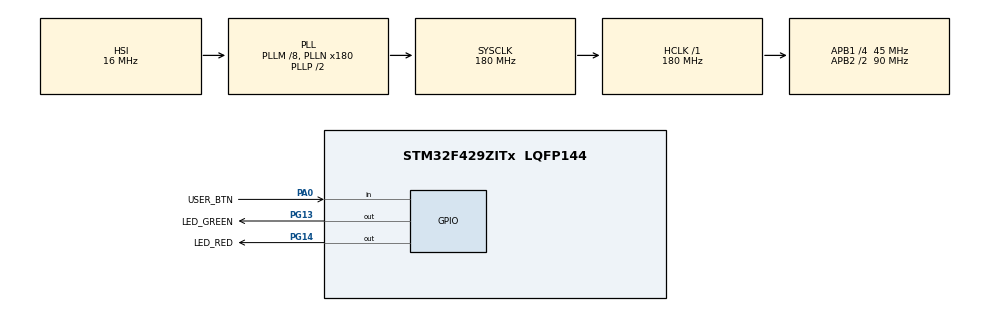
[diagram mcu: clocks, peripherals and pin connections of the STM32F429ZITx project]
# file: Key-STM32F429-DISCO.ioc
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Mcu.Family=STM32F4
Mcu.Name=STM32F429ZITx
Mcu.Package=LQFP144
NVIC.PriorityGroup=NVIC_PRIORITYGROUP_4
NVIC.TIM7_IRQn=true\:0\:0\:false\:false\:true\:true\:true
PA0/WKUP.GPIO_Label=USER_BTN
PA0/WKUP.Signal=GPIO_Input
PG13.GPIO_Label=LED_GREEN
PG13.Signal=GPIO_Output
PG14.GPIO_Label=LED_RED
PG14.Signal=GPIO_Output
ProjectManager.HeapSize=0x200
ProjectManager.StackSize=0x400
ProjectManager.TargetToolchain=MDK-ARM V5.27
RCC.48MHZClocksFreq_Value=120000000
RCC.AHBFreq_Value=180000000
RCC.APB1CLKDivider=RCC_HCLK_DIV4
RCC.APB1Freq_Value=45000000
RCC.APB1TimFreq_Value=90000000
RCC.APB2CLKDivider=RCC_HCLK_DIV2
RCC.APB2Freq_Value=90000000
RCC.APB2TimFreq_Value=180000000
RCC.CortexFreq_Value=180000000
RCC.HCLKFreq_Value=180000000
RCC.HSE_VALUE=8000000
RCC.HSI_VALUE=16000000
RCC.LSE_VALUE=32768
RCC.PLLM=8
RCC.PLLN=180
RCC.PLLQ=3
RCC.PLLSAIN=50
RCC.SYSCLKFreq_VALUE=180000000
RCC.SYSCLKSource=RCC_SYSCLKSOURCE_PLLCLK
RCC.VCOOutputFreq_Value=360000000
TIM7.Period=49999
TIM7.Prescaler=999
VP_TIM7_VS_ClockSourceINT.Mode=Enable_Timer
board=STM32F429I-DISC1

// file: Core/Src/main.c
/* USER CODE BEGIN Header */
/**
  ******************************************************************************
  * @file           : main.c
  * @brief          : Main program body
  ******************************************************************************
  * @attention
  *
  * <h2><center>&copy; Copyright (c) 2022 STMicroelectronics.
  * All rights reserved.</center></h2>
  *
  * This software component is licensed by ST under BSD 3-Clause license,
  * the "License"; You may not use this file except in compliance with the
  * License. You may obtain a copy of the License at:
  *                        opensource.org/licenses/BSD-3-Clause
  *
  ******************************************************************************
  */
/* USER CODE END Header */
#include "main.h"

/* USER CODE BEGIN Includes */
#include "Key.h"
#include "KeyPort.h"

#if !KEY_MULTI_CALLBACK
  #error "You ust enable KEY_MULTI_CALLBACK"
#endif

/* USER CODE END Includes */

TIM_HandleTypeDef htim7;

/* USER CODE BEGIN PV */
static const Key_PinConfig USER_BTN_CONFIG = {
  USER_BTN_GPIO_Port,
  USER_BTN_Pin,
};

#if KEY_MAX_NUM == -1
  static Key userBtn;
#else
  static Key* userBtn;
#endif
/* USER CODE END PV */

void SystemClock_Config(void);
static void MX_GPIO_Init(void);
static void MX_TIM7_Init(void);
/* USER CODE BEGIN PFP */
Key_HandleStatus Btn_onPress(Key* key, Key_State state);
Key_HandleStatus Btn_onRelease(Key* key, Key_State state);
Key_HandleStatus Btn_onHold(Key* key, Key_State state);
/* USER CODE END PFP */

/* USER CODE BEGIN 0 */
void Key_initPin(const Key_PinConfig* config);
uint8_t Key_readPin(const Key_PinConfig* config);

#if KEY_USE_DEINIT
void Key_deInitPin(const Key_PinConfig* config);
#endif

static const Key_Driver KEY_DRIVER = {
  Key_readPin,
  Key_initPin,
#if KEY_USE_DEINIT
  Key_deInitPin,
#endif
};
/* USER CODE END 0 */

int main(void)
{

  /* MCU Configuration--------------------------------------------------------*/

  /* Reset of all peripherals, Initializes the Flash interface and the Systick. */
  HAL_Init();

  /* Configure the system clock */
  SystemClock_Config();

  /* Initialize all configured peripherals */
  MX_GPIO_Init();
  MX_TIM7_Init();
  /* USER CODE BEGIN 2 */
  Key_init(&KEY_DRIVER);

#if KEY_MAX_NUM == -1
  Key_add(&userBtn, &USER_BTN_CONFIG);
  Key_onPressed(&userBtn, Btn_onPress);
  Key_onReleased(&userBtn, Btn_onRelease);
  Key_onHold(&userBtn, Btn_onHold);
#else
  userBtn = Key_new();
  Key_add(userBtn, &USER_BTN_CONFIG);
  Key_onPressed(userBtn, Btn_onPress);
  Key_onReleased(userBtn, Btn_onRelease);
  Key_onHold(userBtn, Btn_onHold);
#endif
  /* USER CODE END 2 */

  /* Infinite loop */
  while (1)
  {

  }
}

void SystemClock_Config(void)
{
  RCC_OscInitTypeDef RCC_OscInitStruct = {0};
  RCC_ClkInitTypeDef RCC_ClkInitStruct = {0};

  /** Configure the main internal regulator output voltage
  */
  __HAL_RCC_PWR_CLK_ENABLE();
  __HAL_PWR_VOLTAGESCALING_CONFIG(PWR_REGULATOR_VOLTAGE_SCALE1);
  /** Initializes the RCC Oscillators according to the specified parameters
  * in the RCC_OscInitTypeDef structure.
  */
  RCC_OscInitStruct.OscillatorType = RCC_OSCILLATORTYPE_HSI;
  RCC_OscInitStruct.HSIState = RCC_HSI_ON;
  RCC_OscInitStruct.HSICalibrationValue = RCC_HSICALIBRATION_DEFAULT;
  RCC_OscInitStruct.PLL.PLLState = RCC_PLL_ON;
  RCC_OscInitStruct.PLL.PLLSource = RCC_PLLSOURCE_HSI;
  RCC_OscInitStruct.PLL.PLLM = 8;
  RCC_OscInitStruct.PLL.PLLN = 180;
  RCC_OscInitStruct.PLL.PLLP = RCC_PLLP_DIV2;
  RCC_OscInitStruct.PLL.PLLQ = 3;
  if (HAL_RCC_OscConfig(&RCC_OscInitStruct) != HAL_OK)
  {
    Error_Handler();
  }
  /** Activate the Over-Drive mode
  */
  if (HAL_PWREx_EnableOverDrive() != HAL_OK)
  {
    Error_Handler();
  }
  /** Initializes the CPU, AHB and APB buses clocks
  */
  RCC_ClkInitStruct.ClockType = RCC_CLOCKTYPE_HCLK|RCC_CLOCKTYPE_SYSCLK
                              |RCC_CLOCKTYPE_PCLK1|RCC_CLOCKTYPE_PCLK2;
  RCC_ClkInitStruct.SYSCLKSource = RCC_SYSCLKSOURCE_PLLCLK;
  RCC_ClkInitStruct.AHBCLKDivider = RCC_SYSCLK_DIV1;
  RCC_ClkInitStruct.APB1CLKDivider = RCC_HCLK_DIV4;
  RCC_ClkInitStruct.APB2CLKDivider = RCC_HCLK_DIV2;

  if (HAL_RCC_ClockConfig(&RCC_ClkInitStruct, FLASH_LATENCY_5) != HAL_OK)
  {
    Error_Handler();
  }
}

static void MX_TIM7_Init(void)
{

  /* USER CODE BEGIN TIM7_Init 0 */
  // Perido is 50ms
  /* USER CODE END TIM7_Init 0 */

  TIM_MasterConfigTypeDef sMasterConfig = {0};

  htim7.Instance = TIM7;
  htim7.Init.Prescaler = 999;
  htim7.Init.CounterMode = TIM_COUNTERMODE_UP;
  htim7.Init.Period = 4499;
  htim7.Init.AutoReloadPreload = TIM_AUTORELOAD_PRELOAD_DISABLE;
  if (HAL_TIM_Base_Init(&htim7) != HAL_OK)
  {
    Error_Handler();
  }
  sMasterConfig.MasterOutputTrigger = TIM_TRGO_RESET;
  sMasterConfig.MasterSlaveMode = TIM_MASTERSLAVEMODE_DISABLE;
  if (HAL_TIMEx_MasterConfigSynchronization(&htim7, &sMasterConfig) != HAL_OK)
  {
    Error_Handler();
  }
  /* USER CODE BEGIN TIM7_Init 2 */
  HAL_TIM_Base_Start_IT(&htim7);
  /* USER CODE END TIM7_Init 2 */

}

static void MX_GPIO_Init(void)
{
  GPIO_InitTypeDef GPIO_InitStruct = {0};

  /* GPIO Ports Clock Enable */
  __HAL_RCC_GPIOA_CLK_ENABLE();
  __HAL_RCC_GPIOG_CLK_ENABLE();

  /*Configure GPIO pin Output Level */
  HAL_GPIO_WritePin(GPIOG, LED_GREEN_Pin|LED_RED_Pin, GPIO_PIN_RESET);

  /*Configure GPIO pin : USER_BTN_Pin */
  GPIO_InitStruct.Pin = USER_BTN_Pin;
  GPIO_InitStruct.Mode = GPIO_MODE_INPUT;
  GPIO_InitStruct.Pull = GPIO_NOPULL;
  HAL_GPIO_Init(USER_BTN_GPIO_Port, &GPIO_InitStruct);

  /*Configure GPIO pins : LED_GREEN_Pin LED_RED_Pin */
  GPIO_InitStruct.Pin = LED_GREEN_Pin|LED_RED_Pin;
  GPIO_InitStruct.Mode = GPIO_MODE_OUTPUT_PP;
  GPIO_InitStruct.Pull = GPIO_NOPULL;
  GPIO_InitStruct.Speed = GPIO_SPEED_FREQ_LOW;
  HAL_GPIO_Init(GPIOG, &GPIO_InitStruct);

}

/* USER CODE BEGIN 4 */
Key_HandleStatus Btn_onPress(Key* key, Key_State state) {
  HAL_GPIO_WritePin(LED_RED_GPIO_Port, LED_RED_Pin, GPIO_PIN_SET);
  return Key_NotHandled;
}
Key_HandleStatus Btn_onRelease(Key* key, Key_State state) {
  HAL_GPIO_WritePin(LED_RED_GPIO_Port, LED_RED_Pin, GPIO_PIN_RESET);
  HAL_GPIO_WritePin(LED_GREEN_GPIO_Port, LED_GREEN_Pin, GPIO_PIN_RESET);
  return Key_Handled;
}
Key_HandleStatus Btn_onHold(Key* key, Key_State state) {
  HAL_GPIO_TogglePin(LED_GREEN_GPIO_Port, LED_GREEN_Pin);
  return Key_NotHandled;
}

void HAL_TIM_PeriodElapsedCallback(TIM_HandleTypeDef *htim) {
  switch ((uint32_t) htim->Instance) {
    case TIM7_BASE:
      Key_handle();
      break;
  }
}
void Key_initPin(const Key_PinConfig* config) {
  GPIO_InitTypeDef init;
  init.Mode = GPIO_MODE_INPUT;
  init.Pull = GPIO_NOPULL;
  init.Pin = config->Pin;
  init.Speed = GPIO_SPEED_FAST;
  HAL_GPIO_Init(config->IO, &init);
}
uint8_t Key_readPin(const Key_PinConfig* config) {
  return !HAL_GPIO_ReadPin(config->IO, config->Pin);
}

#if KEY_USE_DEINIT
void Key_deInitPin(const Key_PinConfig* config) {
  HAL_GPIO_DeInit(config->IO, config->Pin);
}
#endif
/* USER CODE END 4 */

void Error_Handler(void)
{
  __disable_irq();
  while (1)
  {
  }
}

/************************ (C) COPYRIGHT STMicroelectronics *****END OF FILE****/
